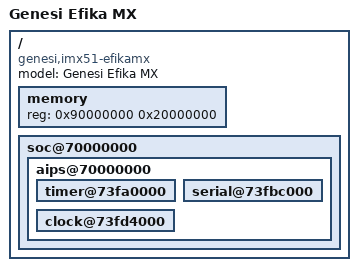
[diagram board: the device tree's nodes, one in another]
/*
 * Copyright (c) 2012 The FreeBSD Foundation
 * All rights reserved.
 *
 * This software was developed by Semihalf under sponsorship from
 * the FreeBSD Foundation.
 *
 * Redistribution and use in source and binary forms, with or without
 * modification, are permitted provided that the following conditions
 * are met:
 * 1. Redistributions of source code must retain the above copyright
 *    notice, this list of conditions and the following disclaimer.
 * 2. Redistributions in binary form must reproduce the above copyright
 *    notice, this list of conditions and the following disclaimer in the
 *    documentation and/or other materials provided with the distribution.
 *
 * THIS SOFTWARE IS PROVIDED BY THE AUTHOR AND CONTRIBUTORS ``AS IS'' AND
 * ANY EXPRESS OR IMPLIED WARRANTIES, INCLUDING, BUT NOT LIMITED TO, THE
 * IMPLIED WARRANTIES OF MERCHANTABILITY AND FITNESS FOR A PARTICULAR PURPOSE
 * ARE DISCLAIMED. IN NO EVENT SHALL THE AUTHOR OR CONTRIBUTORS BE LIABLE
 * FOR ANY DIRECT, INDIRECT, INCIDENTAL, SPECIAL, EXEMPLARY, OR CONSEQUENTIAL
 * DAMAGES (INCLUDING, BUT NOT LIMITED TO, PROCUREMENT OF SUBSTITUTE GOODS
 * OR SERVICES; LOSS OF USE, DATA, OR PROFITS; OR BUSINESS INTERRUPTION)
 * HOWEVER CAUSED AND ON ANY THEORY OF LIABILITY, WHETHER IN CONTRACT, STRICT
 * LIABILITY, OR TORT (INCLUDING NEGLIGENCE OR OTHERWISE) ARISING IN ANY WAY
 * OUT OF THE USE OF THIS SOFTWARE, EVEN IF ADVISED OF THE POSSIBILITY OF
 * SUCH DAMAGE.
 *
 * Freescale i.MX515 Device Tree Source.
 *
 * $FreeBSD$
 */

/dts-v1/;
/include/ "imx51x.dtsi"

/ {
	model = "Genesi Efika MX";
	compatible = "genesi,imx51-efikamx";

	memory {
		/* RAM 512M */
		reg = <0x90000000 0x20000000>;
	};

	soc@70000000 {
		aips@70000000 {
                        timer@73fa0000 {
				status = "okay";
                        };

			/* UART1, console */
			serial@73fbc000 {
				status = "okay";
			};

                        clock@73fd4000 {
				status = "okay";
                        };
		};
	};
};
